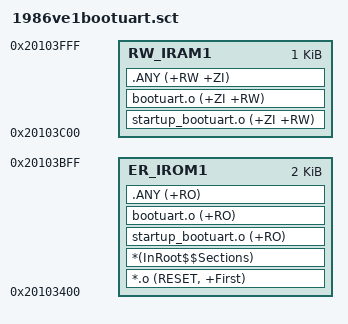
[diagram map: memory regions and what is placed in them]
; *************************************************************
; *** Scatter-Loading Description File generated by uVision ***
; *************************************************************

LR_IROM1 0x20103400 0x00000800  {    ; load region size_region
  ER_IROM1 0x20103400 0x00000800  {  ; load address = execution address
   *.o (RESET, +First)
   *(InRoot$$Sections)
    startup_bootuart.o (+RO)
    bootuart.o (+RO)
   .ANY (+RO)
  }
  RW_IRAM1 0x20103C00 0x00000400  {  ; RW data
    startup_bootuart.o (+ZI +RW)
    bootuart.o (+ZI +RW)
   .ANY (+RW +ZI)
  }
}

